AUTOSAR XML (schema 4-2-2)
package /ComponentTypes
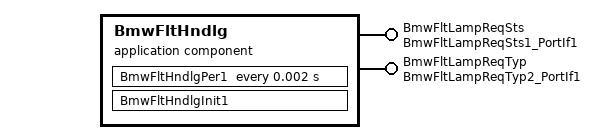
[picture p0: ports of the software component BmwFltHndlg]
  application sw component type BmwFltHndlg  # BMW Fault Handling function provides a functionality of requesting the lamp status whenever the proper indicator status is set to On.
    provide port BmwFltLampReqSts: nonqueued-sender-com-spec{data-element=Val, init-value=0}, provided-interface=BmwFltLampReqSts1_PortIf1
    provide port BmwFltLampReqTyp: nonqueued-sender-com-spec{data-element=Val, init-value=0}, provided-interface=BmwFltLampReqTyp2_PortIf1
    behavior BmwFltHndlg_InternalBehavior
      init event BmwFltHndlg_InitEvent: start-on-event=BmwFltHndlgInit1
      timing event TMT_BmwFltHndlgPer1: start-on-event=BmwFltHndlgPer1, period=0.002
      port-api-options:
        enable-take-address=false, error-handling=NO-TRANSFORMER-ERROR-HANDLING, indirect-api=false, port=BmwFltLampReqSts
        enable-take-address=false, error-handling=NO-TRANSFORMER-ERROR-HANDLING, indirect-api=false, port=BmwFltLampReqTyp
      runnable BmwFltHndlgInit1
      runnable BmwFltHndlgPer1
        data-send-points:
          access SEND_BmwFltLampReqSts_Val: accessed-variable=BmwFltLampReqSts.Val
          access SEND_BmwFltLampReqTyp_Val: accessed-variable=BmwFltLampReqTyp.Val
  swc implementation BmwFltHndlg_Implementation: behavior=BmwFltHndlg_InternalBehavior
    code-descriptors:
      code Default: artifact-descriptors=autosar-engineering-object={short-label=Default, category=SWSRC}
